# STM32G0C1VET6 register map
File version: 1.0
Registers are 32-bit, access not given, reset 0x0 unless marked. A register's access mark holds for its fields unless they carry their own. Offsets are from the block's base; [hi:lo] are bit positions; {n}, {i} and the like mark numbered series.

## USB_DRD_FS
Base 0x40005C00
{0x0+4i} CHEP{i}R (i=0..7)
0x40 CNTR
0x44 ISTR
0x48 FNR
0x4C DADDR
0x54 LPMCSR
0x58 BCDR

## FDCAN1
Base 0x40006400
Same registers: FDCAN2 0x40006800
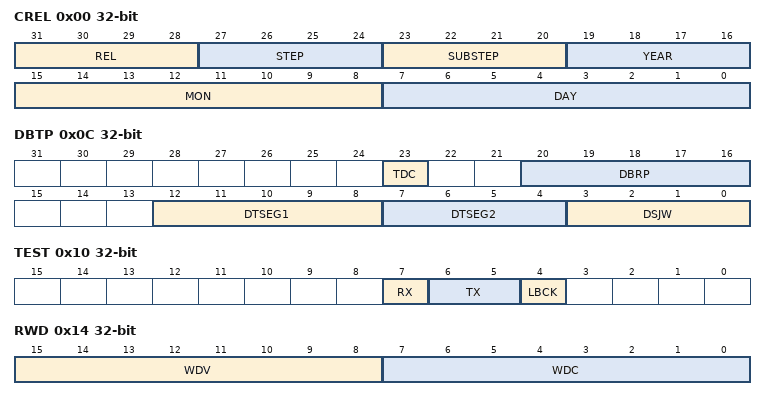
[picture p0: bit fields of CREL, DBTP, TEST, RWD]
0x00 CREL
  [31:28] REL, [27:24] STEP, [23:20] SUBSTEP, [19:16] YEAR, [15:8] MON, [7:0] DAY
0x04 ENDN
  [31:0] ETV
0x0C DBTP
  [23] TDC, [20:16] DBRP, [12:8] DTSEG1, [7:4] DTSEG2, [3:0] DSJW
0x10 TEST
  [7] RX, [6:5] TX, [4] LBCK
0x14 RWD
  [15:8] WDV, [7:0] WDC
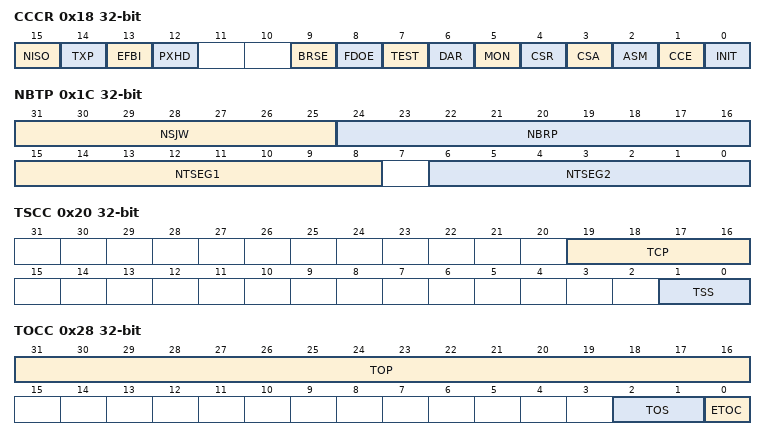
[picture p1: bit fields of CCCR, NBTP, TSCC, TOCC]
0x18 CCCR
  [15] NISO, [14] TXP, [13] EFBI, [12] PXHD, [9] BRSE, [8] FDOE, [7] TEST, [6] DAR, [5] MON, [4] CSR, [3] CSA, [2] ASM, [1] CCE, [0] INIT
0x1C NBTP
  [31:25] NSJW, [24:16] NBRP, [15:8] NTSEG1, [6:0] NTSEG2
0x20 TSCC
  [19:16] TCP, [1:0] TSS
0x24 TSCV
  [15:0] TSC
0x28 TOCC
  [31:16] TOP, [2:1] TOS, [0] ETOC
0x2C TOCV
  [15:0] TOC
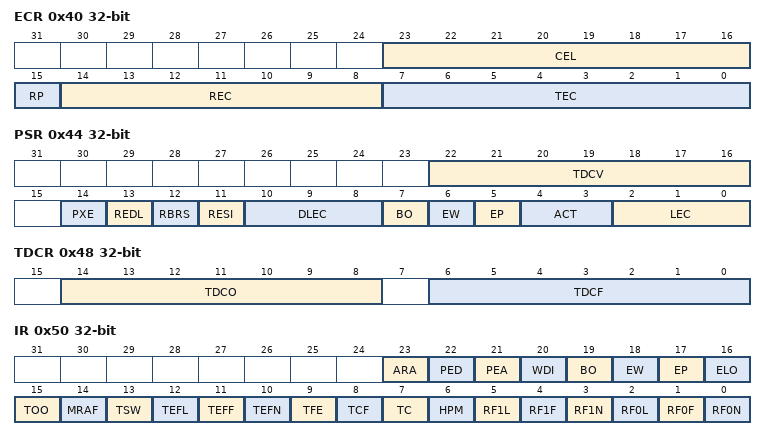
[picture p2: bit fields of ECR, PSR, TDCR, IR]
0x40 ECR
  [23:16] CEL, [15] RP, [14:8] REC, [7:0] TEC
0x44 PSR
  [22:16] TDCV, [14] PXE, [13] REDL, [12] RBRS, [11] RESI, [10:8] DLEC, [7] BO, [6] EW, [5] EP, [4:3] ACT, [2:0] LEC
0x48 TDCR
  [14:8] TDCO, [6:0] TDCF
0x50 IR
  [23] ARA, [22] PED, [21] PEA, [20] WDI, [19] BO, [18] EW, [17] EP, [16] ELO, [15] TOO, [14] MRAF, [13] TSW, [12] TEFL, [11] TEFF, [10] TEFN, [9] TFE, [8] TCF, [7] TC, [6] HPM, [5] RF1L, [4] RF1F, [3] RF1N, [2] RF0L, [1] RF0F, [0] RF0N
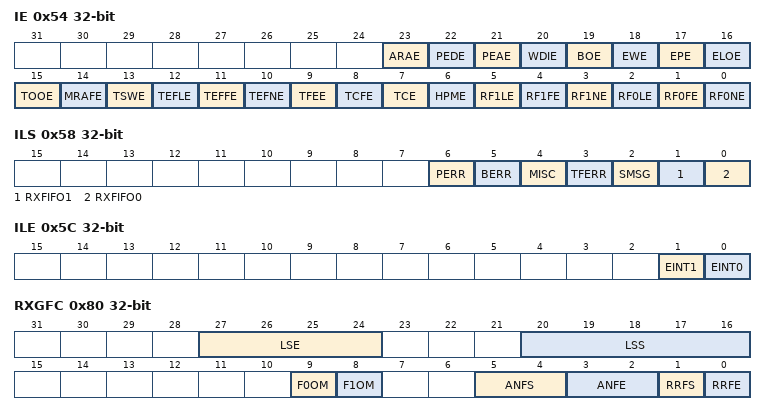
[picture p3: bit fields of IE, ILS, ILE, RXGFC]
0x54 IE
  [23] ARAE, [22] PEDE, [21] PEAE, [20] WDIE, [19] BOE, [18] EWE, [17] EPE, [16] ELOE, [15] TOOE, [14] MRAFE, [13] TSWE, [12] TEFLE, [11] TEFFE, [10] TEFNE, [9] TFEE, [8] TCFE, [7] TCE, [6] HPME, [5] RF1LE, [4] RF1FE, [3] RF1NE, [2] RF0LE, [1] RF0FE, [0] RF0NE
0x58 ILS
  [6] PERR, [5] BERR, [4] MISC, [3] TFERR, [2] SMSG, [1] RXFIFO1, [0] RXFIFO0
0x5C ILE
  [1] EINT1, [0] EINT0
0x80 RXGFC
  [27:24] LSE, [20:16] LSS, [9] F0OM, [8] F1OM, [5:4] ANFS, [3:2] ANFE, [1] RRFS, [0] RRFE
0x84 XIDAM
  [28:0] EIDM
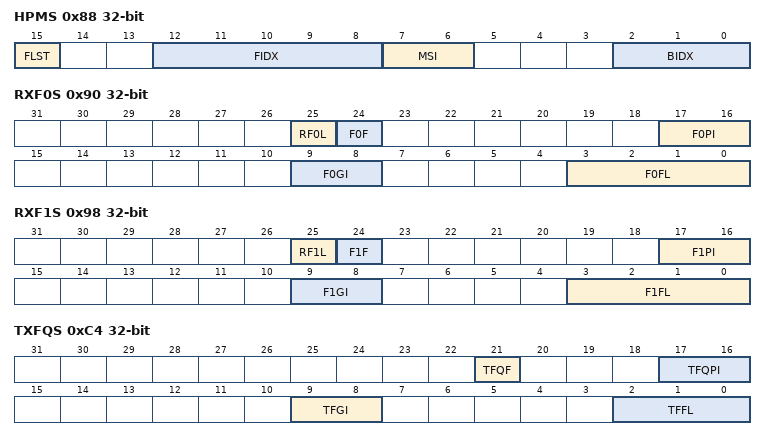
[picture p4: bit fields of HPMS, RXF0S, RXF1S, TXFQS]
0x88 HPMS
  [15] FLST, [12:8] FIDX, [7:6] MSI, [2:0] BIDX
0x90 RXF0S
  [25] RF0L, [24] F0F, [17:16] F0PI, [9:8] F0GI, [3:0] F0FL
0x94 RXF0A
  [2:0] F0AI
0x98 RXF1S
  [25] RF1L, [24] F1F, [17:16] F1PI, [9:8] F1GI, [3:0] F1FL
0x9C RXF1A
  [2:0] F1AI
0xC0 TXBC
  [24] TFQM
0xC4 TXFQS
  [21] TFQF, [17:16] TFQPI, [9:8] TFGI, [2:0] TFFL
0xC8 TXBRP
  [2:0] TRP
0xCC TXBAR
  [2:0] AR
0xD0 TXBCR
  [2:0] CR
0xD4 TXBTO
  [2:0] TO
0xD8 TXBCF
  [2:0] CF
0xDC TXBTIE
  [2:0] TIE
0xE0 TXBCIE
  [2:0] CFIE
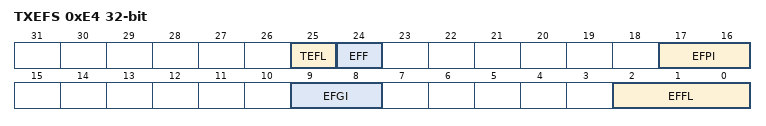
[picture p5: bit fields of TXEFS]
0xE4 TXEFS
  [25] TEFL, [24] EFF, [17:16] EFPI, [9:8] EFGI, [2:0] EFFL
0xE8 TXEFA
  [1:0] EFAI

## FDCAN_CONFIG
Base 0x40006500
0x00 CKDIV
  [3:0] PDIV

## CRS
Base 0x40006C00
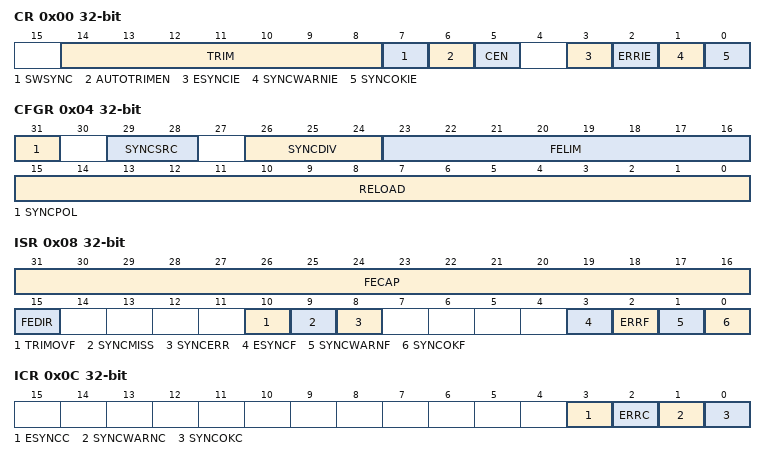
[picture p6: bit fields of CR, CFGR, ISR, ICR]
0x00 CR
  [14:8] TRIM, [7] SWSYNC, [6] AUTOTRIMEN, [5] CEN, [3] ESYNCIE, [2] ERRIE, [1] SYNCWARNIE, [0] SYNCOKIE
0x04 CFGR
  [31] SYNCPOL, [29:28] SYNCSRC, [26:24] SYNCDIV, [23:16] FELIM, [15:0] RELOAD
0x08 ISR
  [31:16] FECAP, [15] FEDIR, [10] TRIMOVF, [9] SYNCMISS, [8] SYNCERR, [3] ESYNCF, [2] ERRF, [1] SYNCWARNF, [0] SYNCOKF
0x0C ICR
  [3] ESYNCC, [2] ERRC, [1] SYNCWARNC, [0] SYNCOKC

## PWR
Base 0x40007000
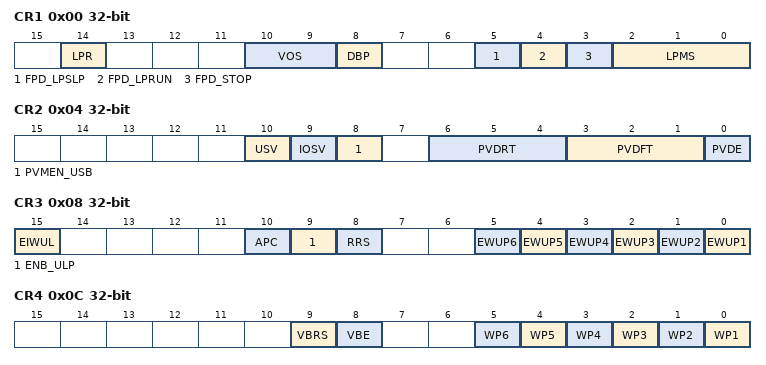
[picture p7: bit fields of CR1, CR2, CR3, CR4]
0x00 CR1
  [14] LPR, [10:9] VOS, [8] DBP, [5] FPD_LPSLP, [4] FPD_LPRUN, [3] FPD_STOP, [2:0] LPMS
0x04 CR2
  [10] USV, [9] IOSV, [8] PVMEN_USB, [6:4] PVDRT, [3:1] PVDFT, [0] PVDE
0x08 CR3
  [15] EIWUL, [10] APC, [9] ENB_ULP, [8] RRS, [n-1] EWUP{n} (n=1..6)
0x0C CR4
  [9] VBRS, [8] VBE, [n-1] WP{n} (n=1..6)
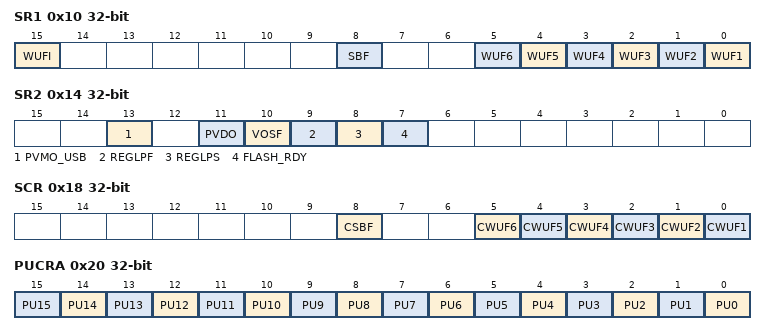
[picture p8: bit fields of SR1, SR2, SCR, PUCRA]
0x10 SR1
  [15] WUFI, [8] SBF, [n-1] WUF{n} (n=1..6)
0x14 SR2
  [13] PVMO_USB, [11] PVDO, [10] VOSF, [9] REGLPF, [8] REGLPS, [7] FLASH_RDY
0x18 SCR
  [8] CSBF, [n-1] CWUF{n} (n=1..6)
0x20 PUCRA
  [n] PU{n} (n=0..15)
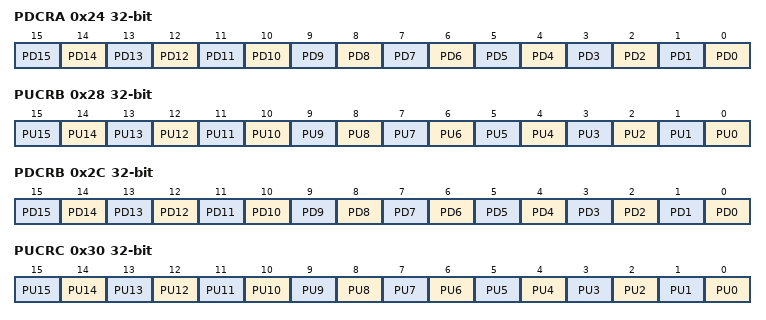
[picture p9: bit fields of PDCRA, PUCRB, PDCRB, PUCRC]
0x24 PDCRA
  [n] PD{n} (n=0..15)
0x28 PUCRB
  [n] PU{n} (n=0..15)
0x2C PDCRB
  [n] PD{n} (n=0..15)
0x30 PUCRC
  [n] PU{n} (n=0..15)
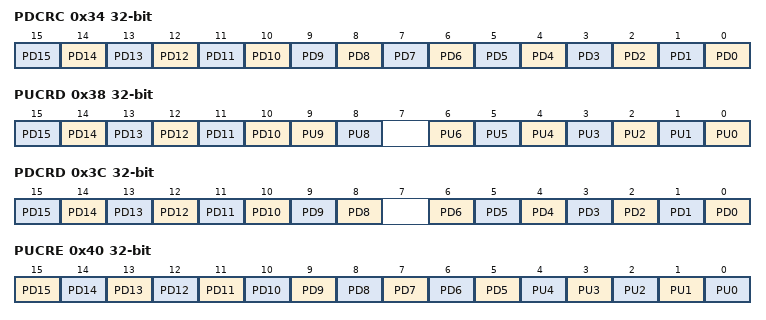
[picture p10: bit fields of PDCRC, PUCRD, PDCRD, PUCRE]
0x34 PDCRC
  [n] PD{n} (n=0..15)
0x38 PUCRD
  [n] PD{n} (n=10..15), [9] PU9, [8] PU8, [n] PU{n} (n=0..6)
0x3C PDCRD
  [n] PD{n} (n=8..15), [n] PD{n} (n=0..6)
0x40 PUCRE
  [n] PD{n} (n=5..15), [n] PU{n} (n=0..4)
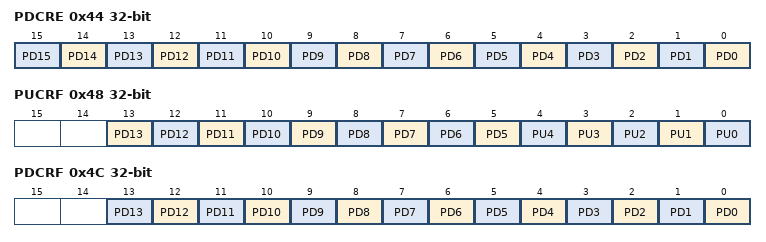
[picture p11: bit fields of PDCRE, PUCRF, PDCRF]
0x44 PDCRE
  [n] PD{n} (n=0..15)
0x48 PUCRF
  [n] PD{n} (n=5..13), [n] PU{n} (n=0..4)
0x4C PDCRF
  [n] PD{n} (n=0..13)
